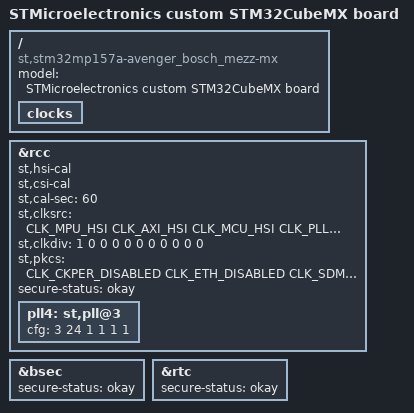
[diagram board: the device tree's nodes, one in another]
/* SPDX-License-Identifier: (GPL-2.0+ OR BSD-3-Clause) */
/*
 * Copyright (C) STMicroelectronics 2019 - All Rights Reserved
 * Author: STM32CubeMX code generation for STMicroelectronics.
 */

/dts-v1/;
#include <dt-bindings/clock/stm32mp1-clksrc.h>

#include "stm32mp157c.dtsi"
#include "stm32mp157cac-pinctrl.dtsi"
/* !!! log : Warning - DDR not configured: unknown DDR dtsi  !!! */
/*#include "???-ddr.dtsi"*/
#include "stm32mp157c-security.dtsi"

/* USER CODE BEGIN includes */
/* USER CODE END includes */

/ {
	model = "STMicroelectronics custom STM32CubeMX board";
	compatible = "st,stm32mp157a-avenger_bosch_mezz-mx", "st,stm32mp157";

	/* USER CODE BEGIN root */
	/* USER CODE END root */

clocks {
    /* USER CODE BEGIN clocks */
    /* USER CODE END clocks */

};

}; /*root*/

&rcc {
    st,hsi-cal;
    st,csi-cal;
    st,cal-sec = <60>;
    st,clksrc = <
        CLK_MPU_HSI
        CLK_AXI_HSI
        CLK_MCU_HSI
        CLK_PLL12_HSI
        CLK_PLL3_HSI
        CLK_PLL4_HSI
        CLK_RTC_LSI
        CLK_MCO1_DISABLED
        CLK_MCO2_DISABLED
    >;
    st,clkdiv = <
        1         /*MPU*/
        0         /*AXI*/
        0         /*MCU*/
        0         /*APB1*/
        0         /*APB2*/
        0         /*APB3*/
        0         /*APB4*/
        0         /*APB5*/
        0         /*RTC*/
        0         /*MCO1*/
        0         /*MCO2*/
    >;
    st,pkcs = <
        CLK_CKPER_DISABLED
        CLK_ETH_DISABLED
        CLK_SDMMC12_DISABLED
        CLK_STGEN_HSI
        CLK_USBPHY_DISABLED
        CLK_SPI2S1_DISABLED
        CLK_SPI2S23_PLL4P
        CLK_SPI45_DISABLED
        CLK_SPI6_DISABLED
        CLK_I2C46_DISABLED
        CLK_SDMMC3_DISABLED
        CLK_ADC_DISABLED
        CLK_CEC_DISABLED
        CLK_I2C12_PCLK1
        CLK_I2C35_DISABLED
        CLK_UART1_DISABLED
        CLK_UART24_DISABLED
        CLK_UART35_DISABLED
        CLK_UART6_DISABLED
        CLK_UART78_DISABLED
        CLK_SPDIF_DISABLED
        CLK_SAI1_DISABLED
        CLK_SAI2_DISABLED
        CLK_SAI3_DISABLED
        CLK_SAI4_DISABLED
        CLK_LPTIM1_DISABLED
        CLK_LPTIM23_DISABLED
        CLK_LPTIM45_DISABLED
    >;
    pll4:st,pll@3 {
        cfg = < 3 24 1 1 1 1>;
    };
};

&bsec{
    status = "okay";
    secure-status = "okay";

    /* USER CODE BEGIN bsec */
    /* USER CODE END bsec */
};

&rcc{
    status = "okay";
    secure-status = "okay";

    /* USER CODE BEGIN rcc */
    /* USER CODE END rcc */
};

&rtc{
    status = "okay";
    secure-status = "okay";

    /* USER CODE BEGIN rtc */
    /* USER CODE END rtc */
};

/* USER CODE BEGIN addons */
/* USER CODE END addons */

